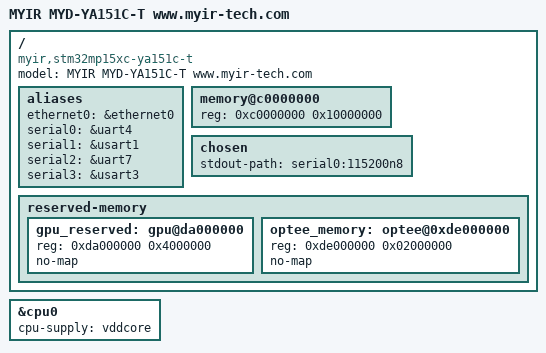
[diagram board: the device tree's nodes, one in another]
// SPDX-License-Identifier: (GPL-2.0+ OR BSD-3-Clause)
/*
 * Based on stm32mp157a device number configuration
 * Author: licy.li@myirtech.com
 */

/dts-v1/;

#include "stm32mp157.dtsi"
#include "stm32mp15xa.dtsi" 
#include "stm32mp15xc-ya15xc-t-pinctrl.dtsi"
#include "stm32mp15xxac-pinctrl.dtsi"
#include "stm32mp15xx-ya15xc-t.dtsi"

/ {
	model = "MYIR MYD-YA151C-T  www.myir-tech.com";
	compatible = "myir,stm32mp15xc-ya151c-t", "st,stm32mp157";

	aliases {
                ethernet0 = &ethernet0;
                serial0 = &uart4; //debug
                serial1 = &usart1; //bt
                serial2 = &uart7; //rs232
                serial3 = &usart3; //rs485

        };
	
	memory@c0000000 {
		device_type = "memory";
		reg = <0xc0000000 0x10000000>;
	};

	chosen {
		stdout-path = "serial0:115200n8";
	};

	reserved-memory {
		gpu_reserved: gpu@da000000 {
			reg = <0xda000000 0x4000000>;
			no-map;
		};

		optee_memory: optee@0xde000000 {
			reg = <0xde000000 0x02000000>;
			no-map;
		};
	};

};


&cpu0{
	cpu-supply = <&vddcore>;
};






